# DDI_0_OSC register map
Vendor: Texas Instruments
Peripheral module from a debugger description file (folder CC2650).
Registers are 32-bit, read-write, reset 0x0 unless marked. A register's access mark holds for its fields unless they carry their own. Offsets are as the file gives them; lines under a group give offsets from that group; [hi:lo] are bit positions; {n}, {i} and the like mark numbered series; 'fields as' and 'values as' point back to an identical list; <NAME> marks a mode.

## AUX_DDI0_OSC — This is the DDI for the digital block that controls all the analog clock oscillators (OSC_DIG) and performs qualification of the clocks generated.
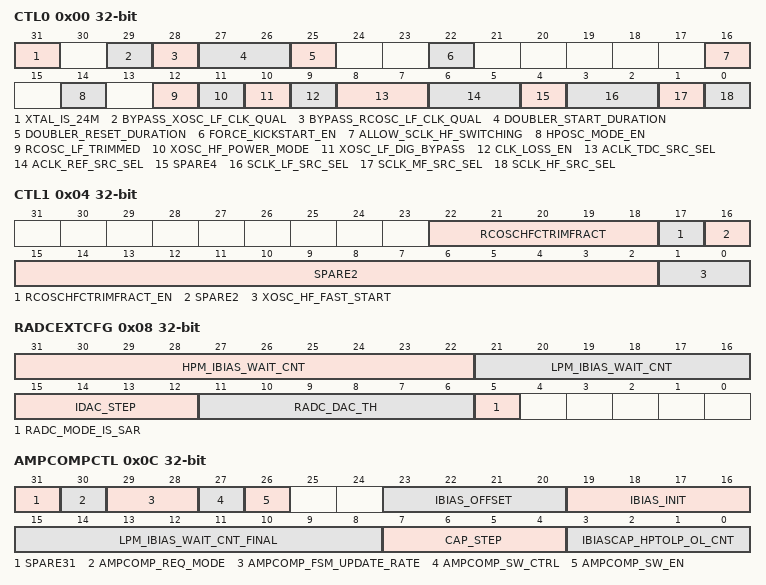
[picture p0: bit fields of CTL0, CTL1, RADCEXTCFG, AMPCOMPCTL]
0x00 CTL0 — Control 0 Controls various clock source selects
  [31] XTAL_IS_24M — Set based on the accurate high frequency XTAL.
    1=Internal. Only to be used through TI provided API.; 0=Internal. Only to be used through TI provided API.
  [29] BYPASS_XOSC_LF_CLK_QUAL — Internal. Only to be used through TI provided API.
  [28] BYPASS_RCOSC_LF_CLK_QUAL — Internal. Only to be used through TI provided API.
  [27:26] DOUBLER_START_DURATION — Internal. Only to be used through TI provided API.
  [25] DOUBLER_RESET_DURATION — Internal. Only to be used through TI provided API.
  [22] FORCE_KICKSTART_EN — Internal. Only to be used through TI provided API.
  [16] ALLOW_SCLK_HF_SWITCHING — 0: Default - Switching of HF clock source is disabled . 1: Allows swtiching of sclk_hf source. Provided to prevent switching of the SCLK_HF source when running from flash (a long period during switching could corrupt flash). When sclk_hf switching is disabled, a new source can be started when SCLK_HF_SRC_SEL is changed, but the switch will not occur until this bit is set. This bit should be set to enable clock switching after STAT0.PENDINGSCLKHFSWITCHING indicates the new HF clock is ready. When switching completes (also indicated by STAT0.PENDINGSCLKHFSWITCHING) sclk_hf switching should be disabled to prevent flash corruption. Switching should not be enabled when running from flash.
  [14] HPOSC_MODE_EN — 0: HPOSC mode is not enabled. The high frequency crystal is assumed to be used as the synth reference clock. 1: Enables 'HPOSC' mode. When used the high frequency crystal clock is assumed to be replaced with a HPOSC resonator. The synth reference clock will come from the HPOSC.
  [12] RCOSC_LF_TRIMMED — Internal. Only to be used through TI provided API.
  [11] XOSC_HF_POWER_MODE — Internal. Only to be used through TI provided API.
  [10] XOSC_LF_DIG_BYPASS — Bypass XOSC_LF and use the digital input clock from AON for the xosc_lf clock.. 0: Use 32kHz XOSC as xosc_lf clock source 1: Use digital input (from AON) as xosc_lf clock source. This bit will only have effect when SCLK_LF_SRC_SEL is selecting the xosc_lf as the sclk_lf source. The muxing performed by this bit is not glitch free. The following procedure should be followed when changing this field to avoid glitches on sclk_lf.. 1) Set SCLK_LF_SRC_SEL to select any source other than the xosc_lf clock source. 2) Set or clear this bit to bypass or not bypass the xosc_lf. 3) Set SCLK_LF_SRC_SEL to use xosc_lf. It is recommended that either the rcosc_hf or xosc_hf (whichever is currently active) be selected as the source in step 1 above. This provides a faster clock change.
  [9] CLK_LOSS_EN — Enable clock loss circuit and hence the indicators to system controller. Checks both SCLK_HF and SCLK_LF clock loss indicators. 0: Disable 1: Enable Clock loss detection should be disabled when changing the sclk_lf source. STAT0.SCLK_LF_SRC can be polled to determine when a change to a new sclk_lf source has completed.
  [8:7] ACLK_TDC_SRC_SEL — Source select for aclk_tdc. 00: RCOSC_HF (48MHz) 01: RCOSC_HF (24MHz) 10: XOSC_HF (24MHz) 11: Not used
  [6:5] ACLK_REF_SRC_SEL — Source select for aclk_ref 00: RCOSC_HF desirved (31.25kHz) 01: XOSC_HF derived (31.25kHz) 10: RCOSC_LF (32kHz) 11: XOSC_LF (32.768kHz)
  [4] SPARE4 — Software should not rely on the value of a reserved. Writing any other value than the reset value may result in undefined behavior.
  [3:2] SCLK_LF_SRC_SEL — Source select for sclk_lf
    3=XOSCLF (Low frequency XOSC); 2=RCOSCLF (Low frequency RCOSC); 1=XOSCHFDLF (Low frequency clock derived from High Frequency XOSC); 0=RCOSCHFDLF (Low frequency clock derived from High Frequency RCOSC)
  [1] SCLK_MF_SRC_SEL — Internal. Only to be used through TI provided API.
    1=XCOSCHFDMF (Medium frequency clock derived from high frequency XOSC.); 0=RCOSCHFDMF (Internal. Only to be used through TI provided API.)
  [0] SCLK_HF_SRC_SEL — Source select for sclk_hf
    1=XOSC (High frequency XOSC clk); 0=RCOSC (High frequency RCOSC clk)
0x04 CTL1 — Control 1 This register contains various OSC_DIG configuration
  [22:18] RCOSCHFCTRIMFRACT — Internal. Only to be used through TI provided API.
  [17] RCOSCHFCTRIMFRACT_EN — Internal. Only to be used through TI provided API.
  [16:2] SPARE2 — Software should not rely on the value of a reserved. Writing any other value than the reset value may result in undefined behavior.
  [1:0] XOSC_HF_FAST_START — Internal. Only to be used through TI provided API.
0x08 RADCEXTCFG — RADC External Configuration
  [31:22] HPM_IBIAS_WAIT_CNT — Internal. Only to be used through TI provided API.
  [21:16] LPM_IBIAS_WAIT_CNT — Internal. Only to be used through TI provided API.
  [15:12] IDAC_STEP — Internal. Only to be used through TI provided API.
  [11:6] RADC_DAC_TH — Internal. Only to be used through TI provided API.
  [5] RADC_MODE_IS_SAR — Internal. Only to be used through TI provided API.
0x0C AMPCOMPCTL — Amplitude Compensation Control
  [31] SPARE31 — Software should not rely on the value of a reserved. Writing any other value than the reset value may result in undefined behavior.
  [30] AMPCOMP_REQ_MODE — Internal. Only to be used through TI provided API.
  [29:28] AMPCOMP_FSM_UPDATE_RATE — Internal. Only to be used through TI provided API.
    3=250KHZ (Internal. Only to be used through TI provided API.); 2=500KHZ (Internal. Only to be used through TI provided API.); 1=1MHZ (Internal. Only to be used through TI provided API.); 0=2MHZ (Internal. Only to be used through TI provided API.)
  [27] AMPCOMP_SW_CTRL — Internal. Only to be used through TI provided API.
  [26] AMPCOMP_SW_EN — Internal. Only to be used through TI provided API.
  [23:20] IBIAS_OFFSET — Internal. Only to be used through TI provided API.
  [19:16] IBIAS_INIT — Internal. Only to be used through TI provided API.
  [15:8] LPM_IBIAS_WAIT_CNT_FINAL — Internal. Only to be used through TI provided API.
  [7:4] CAP_STEP — Internal. Only to be used through TI provided API.
  [3:0] IBIASCAP_HPTOLP_OL_CNT — Internal. Only to be used through TI provided API.
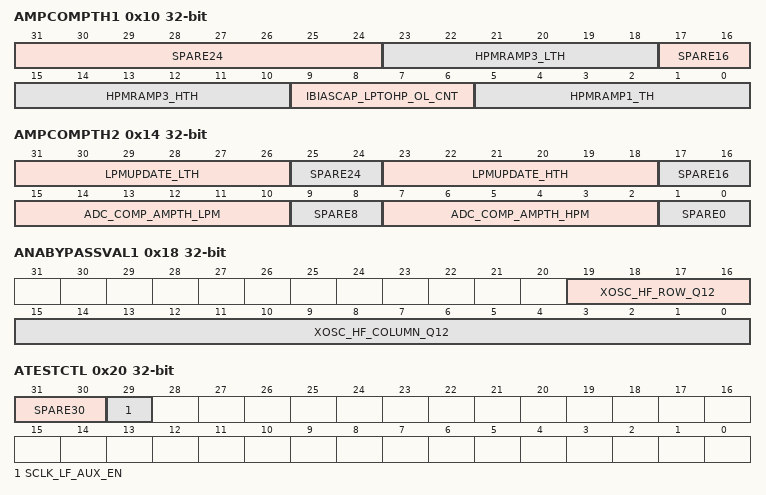
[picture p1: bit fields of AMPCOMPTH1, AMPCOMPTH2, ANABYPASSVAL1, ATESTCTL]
0x10 AMPCOMPTH1 — Amplitude Compensation Threashold 1 This register contains various threshhold values for amplitude compensation algorithm
  [31:24] SPARE24 — Software should not rely on the value of a reserved. Writing any other value than the reset value may result in undefined behavior.
  [23:18] HPMRAMP3_LTH — Internal. Only to be used through TI provided API.
  [17:16] SPARE16 — Software should not rely on the value of a reserved. Writing any other value than the reset value may result in undefined behavior.
  [15:10] HPMRAMP3_HTH — Internal. Only to be used through TI provided API.
  [9:6] IBIASCAP_LPTOHP_OL_CNT — Internal. Only to be used through TI provided API.
  [5:0] HPMRAMP1_TH — Internal. Only to be used through TI provided API.
0x14 AMPCOMPTH2 — Amplitude Compensation Threashold 2 This register contains various threshhold values for amplitude compensation algorithm.
  [31:26] LPMUPDATE_LTH — Internal. Only to be used through TI provided API.
  [25:24] SPARE24 — Software should not rely on the value of a reserved. Writing any other value than the reset value may result in undefined behavior.
  [23:18] LPMUPDATE_HTH — Internal. Only to be used through TI provided API.
  [17:16] SPARE16 — Software should not rely on the value of a reserved. Writing any other value than the reset value may result in undefined behavior.
  [15:10] ADC_COMP_AMPTH_LPM — Internal. Only to be used through TI provided API.
  [9:8] SPARE8 — Software should not rely on the value of a reserved. Writing any other value than the reset value may result in undefined behavior.
  [7:2] ADC_COMP_AMPTH_HPM — Internal. Only to be used through TI provided API.
  [1:0] SPARE0 — Software should not rely on the value of a reserved. Writing any other value than the reset value may result in undefined behavior.
0x18 ANABYPASSVAL1 — Analog Bypass Values 1
  [19:16] XOSC_HF_ROW_Q12 — Internal. Only to be used through TI provided API.
  [15:0] XOSC_HF_COLUMN_Q12 — Internal. Only to be used through TI provided API.
0x1C ANABYPASSVAL2 — Internal. Only to be used through TI provided API.
  [13:0] XOSC_HF_IBIASTHERM
0x20 ATESTCTL — Analog Test Control
  [31:30] SPARE30 — Software should not rely on the value of a reserved. Writing any other value than the reset value may result in undefined behavior.
  [29] SCLK_LF_AUX_EN — Enable 32 kHz clock to AUX_COMPB.
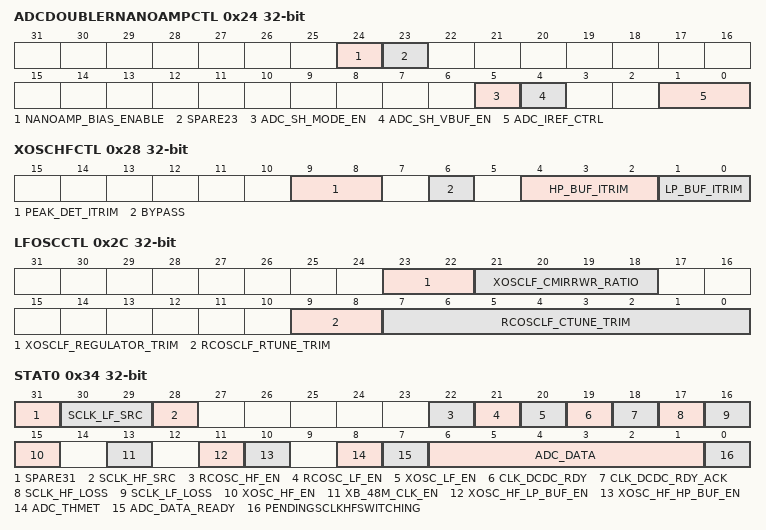
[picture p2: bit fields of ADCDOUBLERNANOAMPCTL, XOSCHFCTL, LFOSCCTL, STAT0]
0x24 ADCDOUBLERNANOAMPCTL — ADC Doubler Nanoamp Control
  [24] NANOAMP_BIAS_ENABLE — Internal. Only to be used through TI provided API.
  [23] SPARE23 — Software should not rely on the value of a reserved. Writing any other value than the reset value may result in undefined behavior
  [5] ADC_SH_MODE_EN — Internal. Only to be used through TI provided API.
  [4] ADC_SH_VBUF_EN — Internal. Only to be used through TI provided API.
  [1:0] ADC_IREF_CTRL — Internal. Only to be used through TI provided API.
0x28 XOSCHFCTL — XOSCHF Control
  [9:8] PEAK_DET_ITRIM — Internal. Only to be used through TI provided API.
  [6] BYPASS — Internal. Only to be used through TI provided API.
  [4:2] HP_BUF_ITRIM — Internal. Only to be used through TI provided API.
  [1:0] LP_BUF_ITRIM — Internal. Only to be used through TI provided API.
0x2C LFOSCCTL — Low Frequency Oscillator Control
  [23:22] XOSCLF_REGULATOR_TRIM — Internal. Only to be used through TI provided API.
  [21:18] XOSCLF_CMIRRWR_RATIO — Internal. Only to be used through TI provided API.
  [9:8] RCOSCLF_RTUNE_TRIM — Internal. Only to be used through TI provided API.
    3=6P0MEG (Internal. Only to be used through TI provided API.); 2=6P5MEG (Internal. Only to be used through TI provided API.); 1=7P0MEG (Internal. Only to be used through TI provided API.); 0=7P5MEG (Internal. Only to be used through TI provided API.)
  [7:0] RCOSCLF_CTUNE_TRIM — Internal. Only to be used through TI provided API.
0x30 RCOSCHFCTL — RCOSCHF Control
  [15:8] RCOSCHF_CTRIM — Internal. Only to be used through TI provided API.
0x34 STAT0 ro — Status 0 This register contains status signals from OSC_DIG
  [31] SPARE31 — Software should not rely on the value of a reserved. Writing any other value than the reset value may result in undefined behavior.
  [30:29] SCLK_LF_SRC — Indicates source for the sclk_lf
    values as CTL0.SCLK_LF_SRC_SEL
  [28] SCLK_HF_SRC — Indicates source for the sclk_hf
    1=XOSC (High frequency XOSC); 0=RCOSC (High frequency RCOSC clk)
  [22] RCOSC_HF_EN
  [21] RCOSC_LF_EN
  [20] XOSC_LF_EN
  [19] CLK_DCDC_RDY
  [18] CLK_DCDC_RDY_ACK
  [17] SCLK_HF_LOSS — Indicates sclk_hf is lost
  [16] SCLK_LF_LOSS — Indicates sclk_lf is lost
  [15] XOSC_HF_EN — Indicates that XOSC_HF is enabled.
  [13] XB_48M_CLK_EN — Indicates that the 48MHz clock from the DOUBLER is enabled. It will be enabled if 24 or 48 MHz chrystal is used (enabled in doulbler bypass for the 48MHz chrystal).
  [11] XOSC_HF_LP_BUF_EN
  [10] XOSC_HF_HP_BUF_EN
  [8] ADC_THMET
  [7] ADC_DATA_READY — indicates when adc_data is ready.
  [6:1] ADC_DATA
  [0] PENDINGSCLKHFSWITCHING — Indicates when sclk_hf is ready to be swtiched
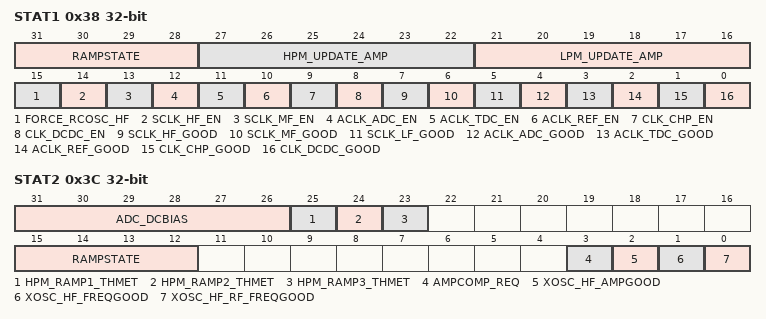
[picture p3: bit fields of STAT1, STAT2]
0x38 STAT1 ro — Status 1 This register contains status signals from OSC_DIG
  [31:28] RAMPSTATE — AMPCOMP FSM State
    14=FAST_START_SETTLE; 13=FAST_START; 12=DUMMY_TO_INIT_1; 11=IDAC_DEC_W_MEASURE (IDAC_DECREMENT_WITH_MEASURE); 10=IBIAS_INC (IBIAS_INCREMENT); 9=LPM_UPDATE; 8=IBIAS_DEC_W_MEASURE (IBIAS_DECREMENT_WITH_MEASURE); 7=IBIAS_CAP_UPDATE; 6=IDAC_INCREMENT; 5=HPM_UPDATE; 4=HPM_RAMP3; 3=HPM_RAMP2; 2=HPM_RAMP1; 1=INITIALIZATION; 0=RESET
  [27:22] HPM_UPDATE_AMP — OSC amplitude during HPM_UPDATE state. When amplitude compensation of XOSC_HF is enabled in high performance mode, this value is the amplitude of the crystal oscillations measured by the on-chip oscillator ADC, divided by 15 mV. For example, a value of 0x20 would indicate that the crystal's amplitude is approximately 480 mV. To enable amplitude compensation, AON_WUC OSCCFG must be set to a non-zero value.
  [21:16] LPM_UPDATE_AMP — OSC amplitude during LPM_UPDATE state When amplitude compensation of XOSC_HF is enabled in low power mode, this value is the amplitude of the crystal oscillations measured by the on-chip oscillator ADC, divided by 15 mV. For example, a value of 0x20 would indicate that the crystal's amplitude is approximately 480 mV. To enable amplitude compensation, AON_WUC OSCCFG must be set to a non-zero value.
  [15] FORCE_RCOSC_HF
  [14] SCLK_HF_EN
  [13] SCLK_MF_EN
  [12] ACLK_ADC_EN
  [11] ACLK_TDC_EN
  [10] ACLK_REF_EN
  [9] CLK_CHP_EN
  [8] CLK_DCDC_EN
  [7] SCLK_HF_GOOD
  [6] SCLK_MF_GOOD
  [5] SCLK_LF_GOOD
  [4] ACLK_ADC_GOOD
  [3] ACLK_TDC_GOOD
  [2] ACLK_REF_GOOD
  [1] CLK_CHP_GOOD
  [0] CLK_DCDC_GOOD
0x3C STAT2 ro — Status 2 This register contains status signals from AMPCOMP FSM
  [31:26] ADC_DCBIAS — DC Bias read by RADC during SAR mode The vaue is an unsigned interger. It is used for debug only.
  [25] HPM_RAMP1_THMET — Indication of threshhold is met for hpm_ramp1
  [24] HPM_RAMP2_THMET — Indication of threshhold is met for hpm_ramp2
  [23] HPM_RAMP3_THMET — Indication of threshhold is met for hpm_ramp3
  [15:12] RAMPSTATE — xosc_hf amplitude compensation FSM This is identical to STAT1.RAMPSTATE. See that description for encoding.
  [3] AMPCOMP_REQ
  [2] XOSC_HF_AMPGOOD — amplitude of xosc_hf is within the required threshold (set by DDI). Not used for anything just for debug/status
  [1] XOSC_HF_FREQGOOD — frequency of xosc_hf is good to use for the digital clocks
  [0] XOSC_HF_RF_FREQGOOD — frequency of xosc_hf is within +/- 20 ppm and xosc_hf is good for radio operations. Used for SW to start synthesizer.
